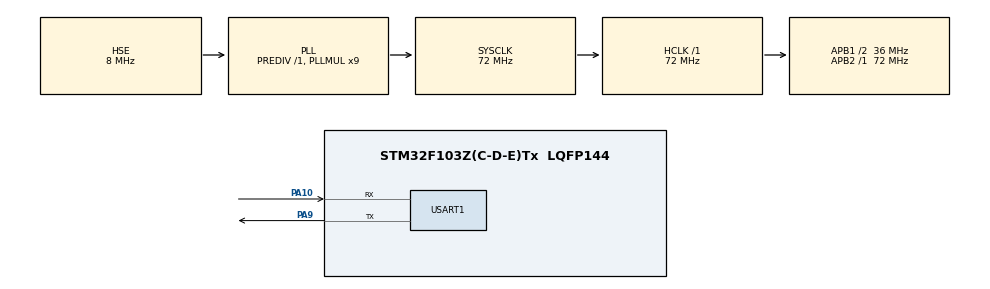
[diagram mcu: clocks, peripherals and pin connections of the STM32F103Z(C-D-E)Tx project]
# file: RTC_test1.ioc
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Mcu.Family=STM32F1
Mcu.Name=STM32F103Z(C-D-E)Tx
Mcu.Package=LQFP144
NVIC.PriorityGroup=NVIC_PRIORITYGROUP_4
OSC_IN.Mode=HSE-External-Oscillator
OSC_IN.Signal=RCC_OSC_IN
OSC_OUT.Mode=HSE-External-Oscillator
OSC_OUT.Signal=RCC_OSC_OUT
PA10.Mode=Asynchronous
PA10.Signal=USART1_RX
PA13.Mode=Serial_Wire
PA13.Signal=SYS_JTMS-SWDIO
PA14.Mode=Serial_Wire
PA14.Signal=SYS_JTCK-SWCLK
PA9.Mode=Asynchronous
PA9.Signal=USART1_TX
PC14-OSC32_IN.Mode=LSE-External-Oscillator
PC14-OSC32_IN.Signal=RCC_OSC32_IN
PC15-OSC32_OUT.Mode=LSE-External-Oscillator
PC15-OSC32_OUT.Signal=RCC_OSC32_OUT
ProjectManager.HeapSize=0x200
ProjectManager.StackSize=0x400
ProjectManager.TargetToolchain=MDK-ARM V5.32
RCC.AHBFreq_Value=72000000
RCC.APB1CLKDivider=RCC_HCLK_DIV2
RCC.APB1Freq_Value=36000000
RCC.APB1TimFreq_Value=72000000
RCC.APB2Freq_Value=72000000
RCC.APB2TimFreq_Value=72000000
RCC.HCLKFreq_Value=72000000
RCC.PLLMUL=RCC_PLL_MUL9
RCC.PLLSourceVirtual=RCC_PLLSOURCE_HSE
RCC.RTCClockSelection=RCC_RTCCLKSOURCE_LSE
RCC.SYSCLKFreq_VALUE=72000000
RCC.SYSCLKSource=RCC_SYSCLKSOURCE_PLLCLK
RCC.USBFreq_Value=72000000
USART1.VirtualMode=VM_ASYNC
VP_RTC_VS_RTC_Activate.Mode=RTC_Enabled
board=custom

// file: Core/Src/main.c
/* USER CODE BEGIN Header */
/**
 ******************************************************************************
 * @file           : main.c
 * @brief          : Main program body
 ******************************************************************************
 * @attention
 *
 * Copyright (c) 2026 STMicroelectronics.
 * All rights reserved.
 *
 * This software is licensed under terms that can be found in the LICENSE file
 * in the root directory of this software component.
 * If no LICENSE file comes with this software, it is provided AS-IS.
 *
 ******************************************************************************
 */
/* USER CODE END Header */
#include "main.h"

/* USER CODE BEGIN Includes */
#include "BSP_Usart_Redir.h"
/* USER CODE END Includes */

/* USER CODE BEGIN PM */
#define RTC_MAGIC_NUMBER 0xABAB
/* USER CODE END PM */

RTC_HandleTypeDef hrtc;

UART_HandleTypeDef huart1;

void SystemClock_Config(void);
static void MX_GPIO_Init(void);
static void MX_USART1_UART_Init(void);
static void MX_RTC_Init(void);

int main(void)
{

  /* MCU Configuration--------------------------------------------------------*/

  /* Reset of all peripherals, Initializes the Flash interface and the Systick. */
  HAL_Init();

  /* Configure the system clock */
  SystemClock_Config();

  /* Initialize all configured peripherals */
  MX_GPIO_Init();
  MX_USART1_UART_Init();
  MX_RTC_Init();
  /* USER CODE BEGIN 2 */
  BSP_Usart_Init(&huart1);

  // HAL_Delay(1000);
  printf("RTC Example Test!\n");

  RTC_TimeTypeDef stim = {
      .Hours = 8, // 12 -> 0001 0010
      .Minutes = 0,
      .Seconds = 0
  };

  // version 1: 每次上电都初始化时间
  // HAL_StatusTypeDef state = HAL_RTC_SetTime(&hrtc, &stim, RTC_FORMAT_BIN);
  // (void)state;
  RTC_TimeTypeDef dTime = {0};

  // version 2 测试代码
  // 1. 获取RTC时间
  // RTC_TimeTypeDef currtime = {0};
  // HAL_RTC_GetTime(&hrtc, &currtime, RTC_FORMAT_BIN);
  // if (currtime.Hours == 0 && currtime.Minutes == 0 && currtime.Seconds == 0) // 有问题！
  // {
  //   printf("首次上电，做初始化!\n");
  //   HAL_StatusTypeDef state = HAL_RTC_SetTime(&hrtc, &stim, RTC_FORMAT_BIN);
  //   (void)state;
  // }

  // versin 3: 备份寄存器，表达是否曾经被初始化过
  uint32_t magic_number = HAL_RTCEx_BKUPRead(&hrtc, RTC_BKP_DR1);
  if(magic_number != RTC_MAGIC_NUMBER)
  {
    printf("首次上电，做初始化!\n");
    HAL_RTCEx_BKUPWrite(&hrtc, RTC_BKP_DR1, RTC_MAGIC_NUMBER);
    HAL_RTC_SetTime(&hrtc, &stim, RTC_FORMAT_BIN);
  }

  // RTC_TimeTypeDef dTime = {0};

  /* USER CODE END 2 */

  /* Infinite loop */
  /* USER CODE BEGIN WHILE */
  while (1)
  {
    HAL_RTC_GetTime(&hrtc, &dTime, RTC_FORMAT_BIN);
    printf("当前时间: %02d:%02d:%02d\n", dTime.Hours, dTime.Minutes, dTime.Seconds);

    HAL_Delay(1000);

    /* USER CODE END WHILE */

  }
}

void SystemClock_Config(void)
{
  RCC_OscInitTypeDef RCC_OscInitStruct = {0};
  RCC_ClkInitTypeDef RCC_ClkInitStruct = {0};
  RCC_PeriphCLKInitTypeDef PeriphClkInit = {0};

  /** Initializes the RCC Oscillators according to the specified parameters
  * in the RCC_OscInitTypeDef structure.
  */
  RCC_OscInitStruct.OscillatorType = RCC_OSCILLATORTYPE_HSE|RCC_OSCILLATORTYPE_LSE;
  RCC_OscInitStruct.HSEState = RCC_HSE_ON;
  RCC_OscInitStruct.HSEPredivValue = RCC_HSE_PREDIV_DIV1;
  RCC_OscInitStruct.LSEState = RCC_LSE_ON;
  RCC_OscInitStruct.HSIState = RCC_HSI_ON;
  RCC_OscInitStruct.PLL.PLLState = RCC_PLL_ON;
  RCC_OscInitStruct.PLL.PLLSource = RCC_PLLSOURCE_HSE;
  RCC_OscInitStruct.PLL.PLLMUL = RCC_PLL_MUL9;
  if (HAL_RCC_OscConfig(&RCC_OscInitStruct) != HAL_OK)
  {
    Error_Handler();
  }

  /** Initializes the CPU, AHB and APB buses clocks
  */
  RCC_ClkInitStruct.ClockType = RCC_CLOCKTYPE_HCLK|RCC_CLOCKTYPE_SYSCLK
                              |RCC_CLOCKTYPE_PCLK1|RCC_CLOCKTYPE_PCLK2;
  RCC_ClkInitStruct.SYSCLKSource = RCC_SYSCLKSOURCE_PLLCLK;
  RCC_ClkInitStruct.AHBCLKDivider = RCC_SYSCLK_DIV1;
  RCC_ClkInitStruct.APB1CLKDivider = RCC_HCLK_DIV2;
  RCC_ClkInitStruct.APB2CLKDivider = RCC_HCLK_DIV1;

  if (HAL_RCC_ClockConfig(&RCC_ClkInitStruct, FLASH_LATENCY_2) != HAL_OK)
  {
    Error_Handler();
  }
  PeriphClkInit.PeriphClockSelection = RCC_PERIPHCLK_RTC;
  PeriphClkInit.RTCClockSelection = RCC_RTCCLKSOURCE_LSE;
  if (HAL_RCCEx_PeriphCLKConfig(&PeriphClkInit) != HAL_OK)
  {
    Error_Handler();
  }
}

static void MX_RTC_Init(void)
{

  /** Initialize RTC Only
  */
  hrtc.Instance = RTC;
  hrtc.Init.AsynchPrediv = RTC_AUTO_1_SECOND;
  hrtc.Init.OutPut = RTC_OUTPUTSOURCE_ALARM;
  if (HAL_RTC_Init(&hrtc) != HAL_OK)
  {
    Error_Handler();
  }

}

static void MX_USART1_UART_Init(void)
{

  huart1.Instance = USART1;
  huart1.Init.BaudRate = 115200;
  huart1.Init.WordLength = UART_WORDLENGTH_8B;
  huart1.Init.StopBits = UART_STOPBITS_1;
  huart1.Init.Parity = UART_PARITY_NONE;
  huart1.Init.Mode = UART_MODE_TX_RX;
  huart1.Init.HwFlowCtl = UART_HWCONTROL_NONE;
  huart1.Init.OverSampling = UART_OVERSAMPLING_16;
  if (HAL_UART_Init(&huart1) != HAL_OK)
  {
    Error_Handler();
  }

}

static void MX_GPIO_Init(void)
{

  /* GPIO Ports Clock Enable */
  __HAL_RCC_GPIOC_CLK_ENABLE();
  __HAL_RCC_GPIOA_CLK_ENABLE();

}

void Error_Handler(void)
{
  __disable_irq();
  while (1)
  {
  }
}
